# AC784x register map
Vendor: AutoChips; Series: AC78; File version: 1.0
CPU: CM4 r0p1, little endian, MPU, FPU, VTOR, 4 interrupt priority bits
Registers are 32-bit, read-write, reset 0x0 unless marked. A register's access mark holds for its fields unless they carry their own. Offsets are from the block's base; [hi:lo] are bit positions; {n}, {i} and the like mark numbered series.

## CTU — Connect Unit Module
Base 0x40006000
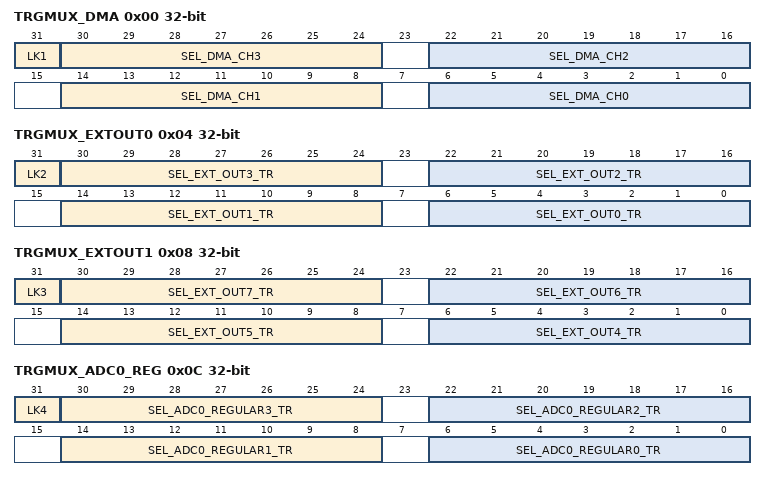
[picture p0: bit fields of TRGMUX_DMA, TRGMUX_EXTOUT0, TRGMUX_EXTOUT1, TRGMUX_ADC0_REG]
0x00 TRGMUX_DMA — TRGMUX Config Register1
  [31] LK1 — TRGMUX register lock
  [8n+6:8n] SEL_DMA_CH{n} (n=0..3) — DMA_CH{n} Hardware Trigger Source
0x04 TRGMUX_EXTOUT0 — TRGMUX Config Register2
  [31] LK2 — TRGMUX register lock
  [8n+6:8n] SEL_EXT_OUT{n}_TR (n=0..3) — EXT_OUT{n} Hardware Trigger Source
0x08 TRGMUX_EXTOUT1 — TRGMUX Config Register3
  [31] LK3 — TRGMUX register lock
  [8n-26:8n-32] SEL_EXT_OUT{n}_TR (n=4..7) — EXT_OUT{n} Hardware Trigger Source
0x0C TRGMUX_ADC0_REG — TRGMUX Config Register4
  [31] LK4 — TRGMUX register lock
  [8n+6:8n] SEL_ADC0_REGULAR{n}_TR (n=0..3) — SEL_ADC0_REGULAR{n} Hardware Trigger Source
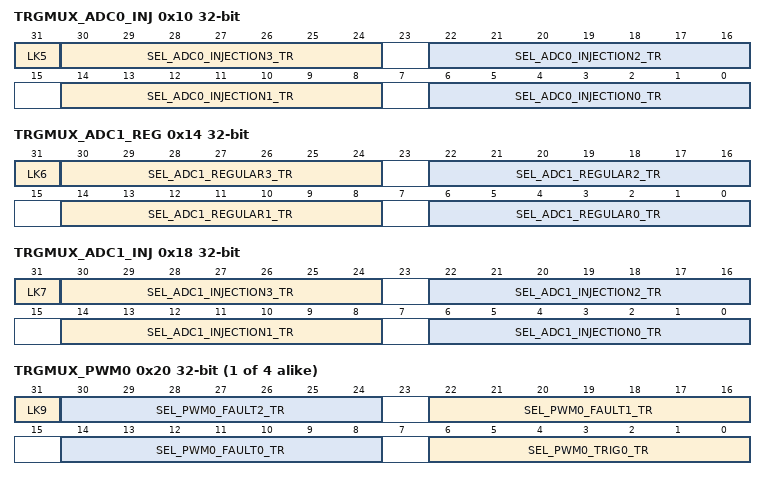
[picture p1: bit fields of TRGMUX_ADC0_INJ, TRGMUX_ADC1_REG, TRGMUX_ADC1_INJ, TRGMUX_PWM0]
0x10 TRGMUX_ADC0_INJ — TRGMUX Config Register5
  [31] LK5 — TRGMUX register lock
  [8n+6:8n] SEL_ADC0_INJECTION{n}_TR (n=0..3) — SEL_ADC0_INJECTION{n} Hardware Trigger Source
0x14 TRGMUX_ADC1_REG — TRGMUX Config Register6
  [31] LK6 — TRGMUX register lock
  [8n+6:8n] SEL_ADC1_REGULAR{n}_TR (n=0..3) — SEL_ADC1_REGULAR{n} Hardware Trigger Source
0x18 TRGMUX_ADC1_INJ — TRGMUX Config Register7
  [31] LK7 — TRGMUX register lock
  [8n+6:8n] SEL_ADC1_INJECTION{n}_TR (n=0..3) — SEL_ADC1_INJECTION{n} Hardware Trigger Source
0x1C TRGMUX_ACMP — TRGMUX Config Register8
  [6:0] SEL_ACMP0_TR — SEL_ACMP0_TR Hardware Trigger Source
{0x20+4i} TRGMUX_PWM{i} (i=0..3) — TRGMUX Config Register{i+9}
  [31] LK{i+9} — TRGMUX register lock
  [30:24] SEL_PWM{i}_FAULT2_TR — PWM{i}_FAULT2 Hardware Trigger Source
  [22:16] SEL_PWM{i}_FAULT1_TR — PWM{i}_FAULT1 Hardware Trigger Source
  [14:8] SEL_PWM{i}_FAULT0_TR — PWM{i}_FAULT0 Hardware Trigger Source
  [6:0] SEL_PWM{i}_TRIG0_TR — PWM{i}_TRIG0 Hardware Trigger Source
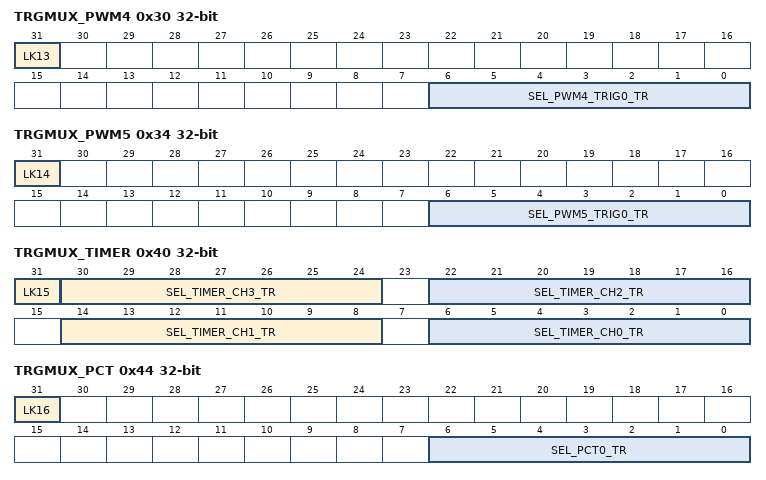
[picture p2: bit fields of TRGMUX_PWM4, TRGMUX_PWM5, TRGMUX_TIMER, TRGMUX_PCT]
0x30 TRGMUX_PWM4 — TRGMUX Config Register13
  [31] LK13 — TRGMUX register lock
  [6:0] SEL_PWM4_TRIG0_TR — PWM4_TRIG0 Hardware Trigger Source
0x34 TRGMUX_PWM5 — TRGMUX Config Register14
  [31] LK14 — TRGMUX register lock
  [6:0] SEL_PWM5_TRIG0_TR — PWM5_TRIG0 Hardware Trigger Source
0x40 TRGMUX_TIMER — TRGMUX Config Register15
  [31] LK15 — TRGMUX register lock
  [8n+6:8n] SEL_TIMER_CH{n}_TR (n=0..3) — TIMER_CH{n} Hardware Trigger Source
0x44 TRGMUX_PCT — TRGMUX Config Register16
  [31] LK16 — TRGMUX register lock
  [6:0] SEL_PCT0_TR — PCT0 Hardware Trigger Source
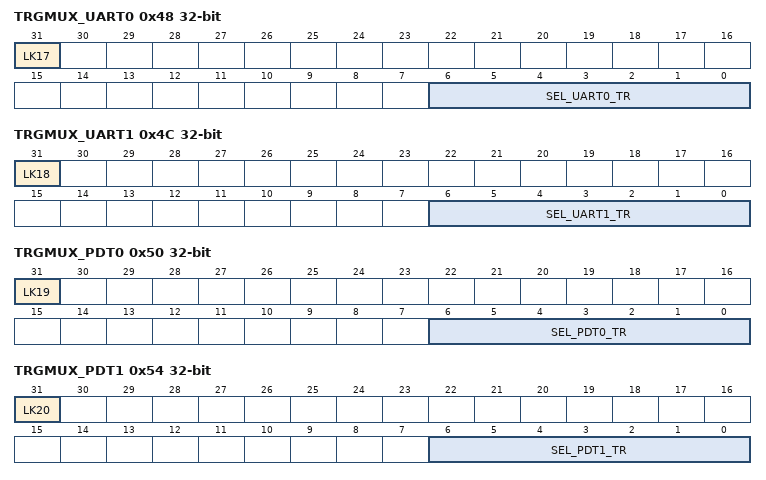
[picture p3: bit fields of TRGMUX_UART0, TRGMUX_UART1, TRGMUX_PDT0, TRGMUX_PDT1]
0x48 TRGMUX_UART0 — TRGMUX Config Register17
  [31] LK17 — TRGMUX register lock
  [6:0] SEL_UART0_TR — UART0 Hardware Trigger Source
0x4C TRGMUX_UART1 — TRGMUX Config Register18
  [31] LK18 — TRGMUX register lock
  [6:0] SEL_UART1_TR — UART1 Hardware Trigger Source
0x50 TRGMUX_PDT0 — TRGMUX Config Register19
  [31] LK19 — TRGMUX register lock
  [6:0] SEL_PDT0_TR — PDT0 Hardware Trigger Source
0x54 TRGMUX_PDT1 — TRGMUX Config Register20
  [31] LK20 — TRGMUX register lock
  [6:0] SEL_PDT1_TR — PDT1 Hardware Trigger Source
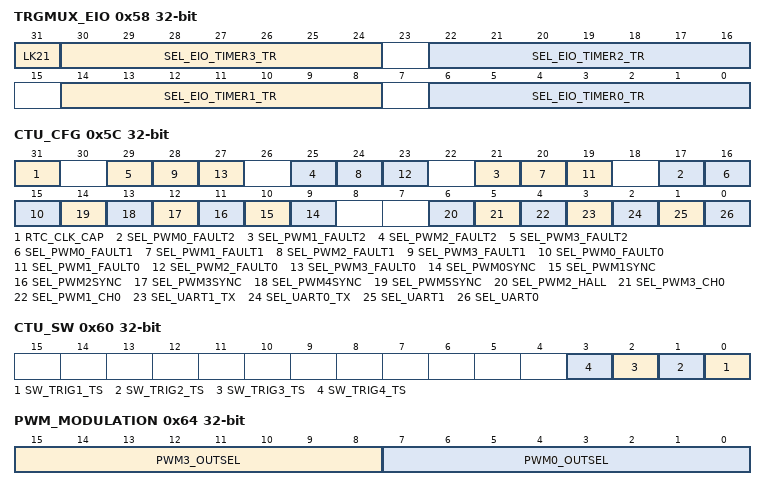
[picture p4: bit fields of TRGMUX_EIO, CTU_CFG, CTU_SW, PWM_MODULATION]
0x58 TRGMUX_EIO — TRGMUX Config Register21
  [31] LK21 — TRGMUX register lock
  [8n+6:8n] SEL_EIO_TIMER{n}_TR (n=0..3) — EIO_TIMER{n} Hardware Trigger Source
0x5C CTU_CFG — CTU Config Register
  [31] RTC_CLK_CAP — RTC Clock Capture
    0=TIMER_CH3 capture TIMER_CH3_TT; 1=TIMER_CH3 capture RTC clock signal
  [4n+17] SEL_PWM{n}_FAULT2 (n=0..3) — PWM{n}_FAULT2 Select
    0=PWM{n}_FAULT2_IN_PIN input signal is connected to the PWM module; 1=PWM{n}_FAULT2_TT input signal is connected to the PWM module
  [4n+16] SEL_PWM{n}_FAULT1 (n=0..3) — PWM{n}_FAULT1 Select
    0=PWM{n}_FAULT1_IN_PIN input signal is connected to the PWM module; 1=PWM{n}_FAULT1_TT input signal is connected to the PWM module
  [4n+15] SEL_PWM{n}_FAULT0 (n=0..3) — PWM{n}_FAULT0 Select
    0=PWM{n}_FAULT0_IN_PIN input signal is connected to the PWM module; 1=PWM{n}_FAULT0_TT input signal is connected to the PWM module
  [n+9] SEL_PWM{n}SYNC (n=0..5) — PWM{n} Synchronization Select
    0=no synchronization triggered; 1=generates a PWM{n} synchronization trigger to the PWM Modules
  [6] SEL_PWM2_HALL — PWM2 CHX Select
    0=PWM2_CHX_IN_PIN; 1=ACMP_HALLA/ACMP_HALLB/ACMP_HALLC
  [5] SEL_PWM3_CH0 — PWM3 CH0 Select
    0=PWM2_CH0_IN_PIN; 1=ACMP0_OUT
  [4] SEL_PWM1_CH0 — PWM1 capture ACMP output
    0=PWM1_CH0_IN_PIN input signal is connected to PWM module directly; 1=ACMP0_OUT input signal is connected to PWM module directly
  [3] SEL_UART1_TX — UART1 modulation
    0=no modulation with UART1 trigger target; 1=modulation with UART1 trigger target
  [2] SEL_UART0_TX — UART0 modulation
    0=no modulation with UART0 trigger target; 1=modulation with UART0 trigger target
  [1] SEL_UART1 — UART1 RxD Filter Select
    0=RXD1 input signal is connected to UART0 module directly; 1=RXD1 input signal is filtered by ACMP0,then injected to UART1
  [0] SEL_UART0 — UART0 RxD Filter Select
    0=RXD0 input signal is connected to UART0 module directly; 1=RXD0 input signal is filtered by ACMP0,then injected to UART0
0x60 CTU_SW — CTU Config2 Register
  [n-1] SW_TRIG{n}_TS (n=1..4) — Software Trigger Source
0x64 PWM_MODULATION — CTU Config3 Register
  [15:8] PWM3_OUTSEL — PWM3 channel modulation select with PWM2_CH1
    0=No Modulation with PWM2_CH1; 1=Modulation with PWM2_CH1
  [7:0] PWM0_OUTSEL — PWM0 channel modulation select with PWM1_CH1
    0=No Modulation with PWM1_CH1; 1=Modulation with PWM1_CH1
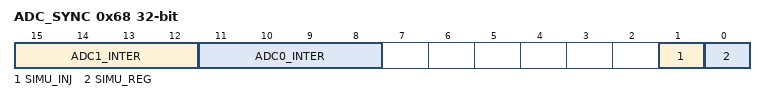
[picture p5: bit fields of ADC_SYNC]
0x68 ADC_SYNC — CTU ADC Interleave and Simultaneous Mode Register
  [15:12] ADC1_INTER — ADC1 Interleave Mode Config
  [11:8] ADC0_INTER — ADC0 Interleave Mode Config
  [1] SIMU_INJ — ADC0/1 Injection Group Simultaneous Mode Enable
  [0] SIMU_REG — ADC0/1 Regular Group Simultaneous Mode Enable
